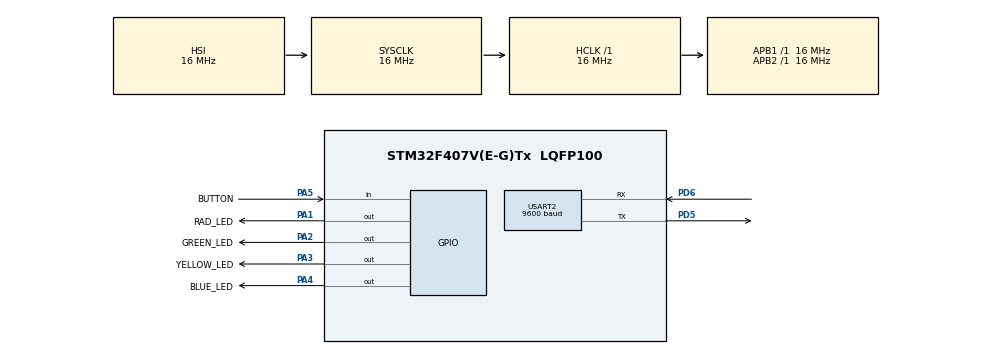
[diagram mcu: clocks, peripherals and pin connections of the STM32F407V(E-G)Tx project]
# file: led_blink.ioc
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FREERTOS.Tasks01=defaultTask,24,128,StartDefaultTask,Default,NULL,Dynamic,NULL,NULL;blink_task,55,128,blink_task_entry,Default,NULL,Dynamic,NULL,NULL
Mcu.Family=STM32F4
Mcu.Name=STM32F407V(E-G)Tx
Mcu.Package=LQFP100
NVIC.PriorityGroup=NVIC_PRIORITYGROUP_4
NVIC.USART2_IRQn=true\:0\:0\:false\:false\:true\:false\:true\:true
PA1.GPIO_Label=RAD_LED
PA1.Signal=GPIO_Output
PA13.Mode=Serial_Wire
PA13.Signal=SYS_JTMS-SWDIO
PA14.Mode=Serial_Wire
PA14.Signal=SYS_JTCK-SWCLK
PA2.GPIO_Label=GREEN_LED
PA2.Signal=GPIO_Output
PA3.GPIO_Label=YELLOW_LED
PA3.Signal=GPIO_Output
PA4.GPIO_Label=BLUE_LED
PA4.Signal=GPIO_Output
PA5.GPIO_Label=BUTTON
PA5.Signal=GPIO_Input
PD5.Mode=Asynchronous
PD5.Signal=USART2_TX
PD6.Mode=Asynchronous
PD6.Signal=USART2_RX
ProjectManager.HeapSize=0x200
ProjectManager.StackSize=0x400
ProjectManager.TargetToolchain=STM32CubeIDE
RCC.AHBFreq_Value=16000000
RCC.APB1Freq_Value=16000000
RCC.APB2Freq_Value=16000000
RCC.CortexFreq_Value=16000000
RCC.HSE_VALUE=25000000
RCC.HSI_VALUE=16000000
RCC.LSE_VALUE=32768
RCC.SYSCLKFreq_VALUE=16000000
RCC.VCOOutputFreq_Value=192000000
USART2.BaudRate=9600
USART2.VirtualMode=VM_ASYNC
VP_FREERTOS_VS_CMSIS_V2.Mode=CMSIS_V2
board=custom

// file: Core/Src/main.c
/* USER CODE BEGIN Header */
/* USER CODE END Header */
#include "main.h"
#include "FreeRTOS.h"
#include "queue.h"
#include "task.h"
/* USER CODE BEGIN Includes */
#include "lib/UL/spinner/spinner.h"
#include "lib/UL/button_controler/button_controler.h"
#include "lib/drivers/uart/uart.h"
#include "lib/UL/io/io_generic/io_generic.h"
#include "lib/UL/io/io_uart/io_uart.h"
#include "lib/UL/io/io_spi/io_spi.h"
#include "lib/UL/io/io_i2c/io_i2c.h"
/* USER CODE END Includes */

UART_HandleTypeDef huart2;

/* Definitions for defaultTask */
xTaskHandle defaultTaskHandle;
/* Definitions for spinner_task */
xTaskHandle spinner_taskHandle;
/* Definitions for button_task */
xTaskHandle button_taskHandle;
/* Definitions for io_generic_task */
xTaskHandle io_generic_taskHandle;

/* Definitions for spinner_queue_handle */
xQueueHandle spinner_queue_handle;

void SystemClock_Config(void);
static void MX_GPIO_Init(void);
static void MX_USART2_UART_Init(void);
void StartDefaultTask(void *pvParameters);
void spinner_task_entry(void *pvParameters);
void button_task_entry(void *pvParameters);
void io_generic_task_entry(void *pvParameters);

int main(void)
{

    /* MCU Configuration--------------------------------------------------------*/

    /* Reset of all peripherals, Initializes the Flash interface and the Systick. */
    HAL_Init();

    /* Configure the system clock */
    SystemClock_Config();

    /* Initialize all configured peripherals */
    MX_GPIO_Init();
    MX_USART2_UART_Init();
    /* Init scheduler */
    osKernelInitialize();

    /* USER CODE BEGIN RTOS_QUEUES */
    spinner_queue_handle = xQueueCreate(2, sizeof(uint32_t));
    /* USER CODE END RTOS_QUEUES */
    /* Create the thread(s) */
    /* creation of defaultTask */
    xTaskCreate(StartDefaultTask, "defaultTask", 128 * 4, NULL,  1 | portPRIVILEGE_BIT, defaultTaskHandle);
    /* creation of spinner_task */
    xTaskCreate(spinner_task_entry, "spinner_task", 128 * 4, NULL,  4 | portPRIVILEGE_BIT, spinner_taskHandle);
    /* creation of button_task */
    xTaskCreate(button_task_entry, "button_task", 128 * 4, NULL,  3 | portPRIVILEGE_BIT, button_taskHandle);
    /* creation of io_generic_task */
    xTaskCreate(io_generic_task_entry, "io_generic_task", 128 * 4, NULL,  2 | portPRIVILEGE_BIT, io_generic_taskHandle);

    /* Start scheduler */
    osKernelStart();

    /* We should never get here as control is now taken by the scheduler */
    /* Infinite loop */
    /* USER CODE BEGIN WHILE */
    while (1)
    {
    }
    /* USER CODE END 3 */
}

void SystemClock_Config(void)
{
    RCC_OscInitTypeDef RCC_OscInitStruct =
    { 0 };
    RCC_ClkInitTypeDef RCC_ClkInitStruct =
    { 0 };

    /** Configure the main internal regulator output voltage
     */
    __HAL_RCC_PWR_CLK_ENABLE();
    __HAL_PWR_VOLTAGESCALING_CONFIG(PWR_REGULATOR_VOLTAGE_SCALE1);
    /** Initializes the RCC Oscillators according to the specified parameters
     * in the RCC_OscInitTypeDef structure.
     */
    RCC_OscInitStruct.OscillatorType = RCC_OSCILLATORTYPE_HSI;
    RCC_OscInitStruct.HSIState = RCC_HSI_ON;
    RCC_OscInitStruct.HSICalibrationValue = RCC_HSICALIBRATION_DEFAULT;
    RCC_OscInitStruct.PLL.PLLState = RCC_PLL_NONE;
    if (HAL_RCC_OscConfig(&RCC_OscInitStruct) != HAL_OK)
    {
        Error_Handler();
    }
    /** Initializes the CPU, AHB and APB buses clocks
     */
    RCC_ClkInitStruct.ClockType = RCC_CLOCKTYPE_HCLK | RCC_CLOCKTYPE_SYSCLK
            | RCC_CLOCKTYPE_PCLK1 | RCC_CLOCKTYPE_PCLK2;
    RCC_ClkInitStruct.SYSCLKSource = RCC_SYSCLKSOURCE_HSI;
    RCC_ClkInitStruct.AHBCLKDivider = RCC_SYSCLK_DIV1;
    RCC_ClkInitStruct.APB1CLKDivider = RCC_HCLK_DIV1;
    RCC_ClkInitStruct.APB2CLKDivider = RCC_HCLK_DIV1;

    if (HAL_RCC_ClockConfig(&RCC_ClkInitStruct, FLASH_LATENCY_0) != HAL_OK)
    {
        Error_Handler();
    }
}

static void MX_USART2_UART_Init(void)
{

    huart2.Instance = USART2;
    huart2.Init.BaudRate = 9600;
    huart2.Init.WordLength = UART_WORDLENGTH_8B;
    huart2.Init.StopBits = UART_STOPBITS_1;
    huart2.Init.Parity = UART_PARITY_NONE;
    huart2.Init.Mode = UART_MODE_TX_RX;
    huart2.Init.HwFlowCtl = UART_HWCONTROL_NONE;
    huart2.Init.OverSampling = UART_OVERSAMPLING_16;
    if (HAL_UART_Init(&huart2) != HAL_OK)
    {
        Error_Handler();
    }

}

static void MX_GPIO_Init(void)
{
    /* GPIO Ports Clock Enable */
    __HAL_RCC_GPIOA_CLK_ENABLE();
    __HAL_RCC_GPIOD_CLK_ENABLE();
}

void StartDefaultTask(void *pvParameters)
{
    for (;;)
    {
        osDelay(1);
    }
}

/* USER CODE END Header_spinner_task_entry */
void spinner_task_entry(void *pvParameters)
{
    volatile uint32_t spinner_period_ms = 400;
    spinner_init(&spinner_queue_handle);
    /* Infinite loop */
    for (;;)
    {
        if(uxQueueMessagesWaiting(spinner_queue_handle) != 0)
        {
            xQueueReceive(spinner_queue_handle, &spinner_period_ms,0);
        }
        spinner_run();
        vTaskDelay(spinner_period_ms);
    }
    vTaskDelay(0);
}

/* USER CODE END Header_button_task_entry */
void button_task_entry(void *pvParameters)
{
    volatile uint8_t button_read_period_ms = 1;
    button_controler_init();
    /* Infinite loop */
    for (;;)
    {
        button_controler_run();
        vTaskDelay(button_read_period_ms / portTICK_RATE_MS);
    }
    vTaskDelay(0);
}

/* USER CODE END Header_io_configurate_task_entry */
void io_generic_task_entry(void *pvParameters)
{
    io_configurate();
    /* Infinite loop */
    for (;;)
    {
        io_generic_run();
    }
    vTaskDelay(0);
}

void Error_Handler(void)
{

}
